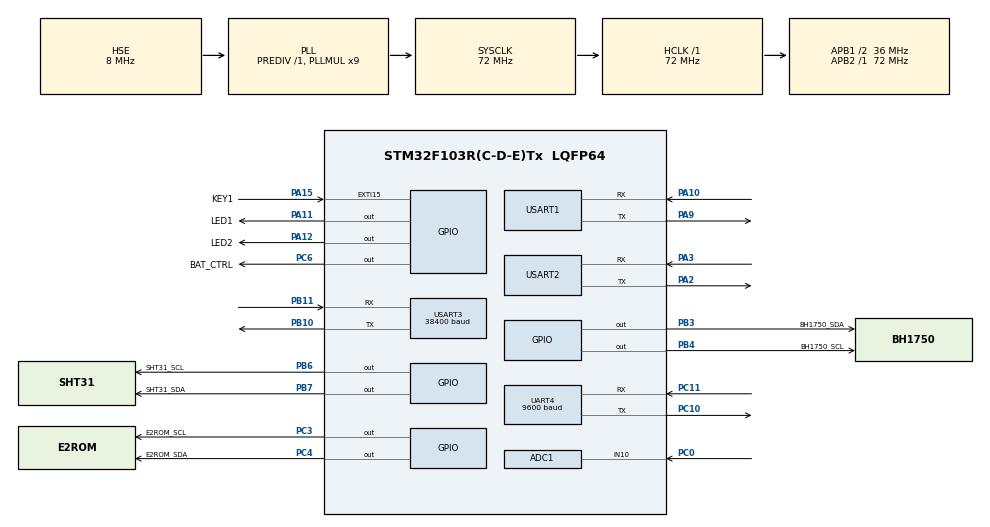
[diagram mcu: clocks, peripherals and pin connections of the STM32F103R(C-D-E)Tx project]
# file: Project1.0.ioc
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ADC1.Channel-0\#ChannelRegularConversion=ADC_CHANNEL_10
ADC1.NbrOfConversionFlag=1
ADC1.Rank-0\#ChannelRegularConversion=1
ADC1.SamplingTime-0\#ChannelRegularConversion=ADC_SAMPLETIME_1CYCLE_5
ADC1.master=1
Dma.Request0=USART2_TX
Dma.Request1=USART2_RX
Dma.Request2=USART3_RX
Dma.USART2_RX.1.Direction=DMA_PERIPH_TO_MEMORY
Dma.USART2_RX.1.Instance=DMA1_Channel6
Dma.USART2_RX.1.MemDataAlignment=DMA_MDATAALIGN_BYTE
Dma.USART2_RX.1.MemInc=DMA_MINC_ENABLE
Dma.USART2_RX.1.Mode=DMA_NORMAL
Dma.USART2_RX.1.PeriphDataAlignment=DMA_PDATAALIGN_BYTE
Dma.USART2_RX.1.PeriphInc=DMA_PINC_DISABLE
Dma.USART2_RX.1.Priority=DMA_PRIORITY_HIGH
Dma.USART2_TX.0.Direction=DMA_MEMORY_TO_PERIPH
Dma.USART2_TX.0.Instance=DMA1_Channel7
Dma.USART2_TX.0.MemDataAlignment=DMA_MDATAALIGN_BYTE
Dma.USART2_TX.0.MemInc=DMA_MINC_ENABLE
Dma.USART2_TX.0.Mode=DMA_NORMAL
Dma.USART2_TX.0.PeriphDataAlignment=DMA_PDATAALIGN_BYTE
Dma.USART2_TX.0.PeriphInc=DMA_PINC_DISABLE
Dma.USART2_TX.0.Priority=DMA_PRIORITY_MEDIUM
Dma.USART3_RX.2.Direction=DMA_PERIPH_TO_MEMORY
Dma.USART3_RX.2.Instance=DMA1_Channel3
Dma.USART3_RX.2.MemDataAlignment=DMA_MDATAALIGN_BYTE
Dma.USART3_RX.2.MemInc=DMA_MINC_ENABLE
Dma.USART3_RX.2.Mode=DMA_NORMAL
Dma.USART3_RX.2.PeriphDataAlignment=DMA_PDATAALIGN_BYTE
Dma.USART3_RX.2.PeriphInc=DMA_PINC_DISABLE
Dma.USART3_RX.2.Priority=DMA_PRIORITY_MEDIUM
IWDG.Prescaler=IWDG_PRESCALER_256
Mcu.Family=STM32F1
Mcu.Name=STM32F103R(C-D-E)Tx
Mcu.Package=LQFP64
NVIC.DMA1_Channel3_IRQn=true\:0\:0\:false\:false\:true\:false\:true
NVIC.DMA1_Channel6_IRQn=true\:0\:0\:true\:false\:true\:false\:true
NVIC.DMA1_Channel7_IRQn=true\:0\:0\:true\:false\:true\:false\:true
NVIC.EXTI15_10_IRQn=true\:9\:0\:true\:false\:true\:true\:true
NVIC.PriorityGroup=NVIC_PRIORITYGROUP_4
NVIC.TIM6_IRQn=true\:8\:0\:true\:false\:true\:true\:true
NVIC.TIM7_IRQn=true\:10\:0\:true\:false\:true\:true\:true
NVIC.UART4_IRQn=true\:6\:0\:true\:false\:true\:true\:true
NVIC.USART1_IRQn=true\:7\:0\:true\:false\:true\:true\:true
NVIC.USART2_IRQn=true\:5\:0\:true\:false\:true\:true\:true
NVIC.USART3_IRQn=true\:6\:0\:true\:false\:true\:true\:true
PA10.Mode=Asynchronous
PA10.Signal=USART1_RX
PA11.GPIO_Label=LED1
PA11.Signal=GPIO_Output
PA12.GPIO_Label=LED2
PA12.Signal=GPIO_Output
PA13.Mode=Serial_Wire
PA13.Signal=SYS_JTMS-SWDIO
PA14.Mode=Serial_Wire
PA14.Signal=SYS_JTCK-SWCLK
PA15.GPIO_Label=KEY1
PA15.Signal=GPXTI15
PA2.Mode=Asynchronous
PA2.Signal=USART2_TX
PA3.Mode=Asynchronous
PA3.Signal=USART2_RX
PA9.Mode=Asynchronous
PA9.Signal=USART1_TX
PB10.Mode=Asynchronous
PB10.Signal=USART3_TX
PB11.Mode=Asynchronous
PB11.Signal=USART3_RX
PB3.GPIO_Label=BH1750_SDA
PB3.GPIO_ModeDefaultOutputPP=GPIO_MODE_OUTPUT_OD
PB3.GPIO_Speed=GPIO_SPEED_FREQ_HIGH
PB3.PinState=GPIO_PIN_SET
PB3.Signal=GPIO_Output
PB4.GPIO_Label=BH1750_SCL
PB4.GPIO_ModeDefaultOutputPP=GPIO_MODE_OUTPUT_OD
PB4.GPIO_Speed=GPIO_SPEED_FREQ_HIGH
PB4.PinState=GPIO_PIN_SET
PB4.Signal=GPIO_Output
PB6.GPIO_Label=SHT31_SCL
PB6.GPIO_ModeDefaultOutputPP=GPIO_MODE_OUTPUT_OD
PB6.GPIO_Speed=GPIO_SPEED_FREQ_HIGH
PB6.PinState=GPIO_PIN_SET
PB6.Signal=GPIO_Output
PB7.GPIO_Label=SHT31_SDA
PB7.GPIO_ModeDefaultOutputPP=GPIO_MODE_OUTPUT_OD
PB7.GPIO_Speed=GPIO_SPEED_FREQ_HIGH
PB7.PinState=GPIO_PIN_SET
PB7.Signal=GPIO_Output
PC0.Signal=ADCx_IN10
PC10.Mode=Asynchronous
PC10.Signal=UART4_TX
PC11.Mode=Asynchronous
PC11.Signal=UART4_RX
PC3.GPIO_Label=E2ROM_SCL
PC3.GPIO_ModeDefaultOutputPP=GPIO_MODE_OUTPUT_OD
PC3.GPIO_Speed=GPIO_SPEED_FREQ_MEDIUM
PC3.PinState=GPIO_PIN_SET
PC3.Signal=GPIO_Output
PC4.GPIO_Label=E2ROM_SDA
PC4.GPIO_ModeDefaultOutputPP=GPIO_MODE_OUTPUT_OD
PC4.GPIO_Speed=GPIO_SPEED_FREQ_MEDIUM
PC4.PinState=GPIO_PIN_SET
PC4.Signal=GPIO_Output
PC6.GPIO_Label=BAT_CTRL
PC6.GPIO_Speed=GPIO_SPEED_FREQ_MEDIUM
PC6.PinState=GPIO_PIN_SET
PC6.Signal=GPIO_Output
PD0-OSC_IN.Mode=HSE-External-Oscillator
PD0-OSC_IN.Signal=RCC_OSC_IN
PD1-OSC_OUT.Mode=HSE-External-Oscillator
PD1-OSC_OUT.Signal=RCC_OSC_OUT
ProjectManager.HeapSize=0x200
ProjectManager.StackSize=0x400
ProjectManager.TargetToolchain=MDK-ARM V5.27
RCC.ADCPresc=RCC_ADCPCLK2_DIV6
RCC.AHBFreq_Value=72000000
RCC.APB1CLKDivider=RCC_HCLK_DIV2
RCC.APB1Freq_Value=36000000
RCC.APB1TimFreq_Value=72000000
RCC.APB2Freq_Value=72000000
RCC.APB2TimFreq_Value=72000000
RCC.HCLKFreq_Value=72000000
RCC.PLLMUL=RCC_PLL_MUL9
RCC.PLLSourceVirtual=RCC_PLLSOURCE_HSE
RCC.SYSCLKFreq_VALUE=72000000
RCC.SYSCLKSource=RCC_SYSCLKSOURCE_PLLCLK
RCC.USBFreq_Value=72000000
SH.ADCx_IN10.0=ADC1_IN10,IN10
TIM6.AutoReloadPreload=TIM_AUTORELOAD_PRELOAD_ENABLE
TIM6.Period=5000
TIM6.Prescaler=71
TIM7.AutoReloadPreload=TIM_AUTORELOAD_PRELOAD_ENABLE
TIM7.Period=50000
TIM7.Prescaler=71
UART4.BaudRate=9600
UART4.VirtualMode=Asynchronous
USART1.VirtualMode=VM_ASYNC
USART2.VirtualMode=VM_ASYNC
USART3.BaudRate=38400
USART3.VirtualMode=VM_ASYNC
VP_IWDG_VS_IWDG.Mode=IWDG_Activate
VP_TIM6_VS_ClockSourceINT.Mode=Enable_Timer
VP_TIM7_VS_ClockSourceINT.Mode=Enable_Timer
board=custom

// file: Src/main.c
/* USER CODE BEGIN Header */
/**
  ******************************************************************************
  * @file           : main.c
  * @brief          : Main program body
  ******************************************************************************
  * @attention
  *
  * <h2><center>&copy; Copyright (c) 2022 STMicroelectronics.
  * All rights reserved.</center></h2>
  *
  * This software component is licensed by ST under BSD 3-Clause license,
  * the "License"; You may not use this file except in compliance with the
  * License. You may obtain a copy of the License at:
  *                        opensource.org/licenses/BSD-3-Clause
  *
  ******************************************************************************
  */
/* USER CODE END Header */

#include "main.h"
#include "adc.h"
#include "dma.h"
#include "iwdg.h"
#include "tim.h"
#include "usart.h"
#include "gpio.h"

/* USER CODE BEGIN Includes */
#include "Myapplication.h"
/* USER CODE END Includes */

void SystemClock_Config(void);

int main(void)
{

  /* MCU Configuration--------------------------------------------------------*/

  /* Reset of all peripherals, Initializes the Flash interface and the Systick. */
  HAL_Init();

  /* Configure the system clock */
  SystemClock_Config();

  /* Initialize all configured peripherals */
  MX_GPIO_Init();
  MX_DMA_Init();
  MX_USART1_UART_Init();
  MX_TIM6_Init();
  MX_UART4_Init();
  MX_USART2_UART_Init();
  MX_USART3_UART_Init();
  MX_ADC1_Init();
  MX_IWDG_Init();
  MX_TIM7_Init();
  /* USER CODE BEGIN 2 */
  MyInit.Peripheral_Set();
  /* USER CODE END 2 */

  /* Infinite loop */
  while (1)
  {

    /* USER CODE BEGIN 3 */
		System.Run();
  }
  /* USER CODE END 3 */
}

void SystemClock_Config(void)
{
  RCC_OscInitTypeDef RCC_OscInitStruct = {0};
  RCC_ClkInitTypeDef RCC_ClkInitStruct = {0};
  RCC_PeriphCLKInitTypeDef PeriphClkInit = {0};

  /** Initializes the CPU, AHB and APB busses clocks
  */
  RCC_OscInitStruct.OscillatorType = RCC_OSCILLATORTYPE_LSI|RCC_OSCILLATORTYPE_HSE;
  RCC_OscInitStruct.HSEState = RCC_HSE_ON;
  RCC_OscInitStruct.HSEPredivValue = RCC_HSE_PREDIV_DIV1;
  RCC_OscInitStruct.HSIState = RCC_HSI_ON;
  RCC_OscInitStruct.LSIState = RCC_LSI_ON;
  RCC_OscInitStruct.PLL.PLLState = RCC_PLL_ON;
  RCC_OscInitStruct.PLL.PLLSource = RCC_PLLSOURCE_HSE;
  RCC_OscInitStruct.PLL.PLLMUL = RCC_PLL_MUL9;
  if (HAL_RCC_OscConfig(&RCC_OscInitStruct) != HAL_OK)
  {
    Error_Handler();
  }
  /** Initializes the CPU, AHB and APB busses clocks
  */
  RCC_ClkInitStruct.ClockType = RCC_CLOCKTYPE_HCLK|RCC_CLOCKTYPE_SYSCLK
                              |RCC_CLOCKTYPE_PCLK1|RCC_CLOCKTYPE_PCLK2;
  RCC_ClkInitStruct.SYSCLKSource = RCC_SYSCLKSOURCE_PLLCLK;
  RCC_ClkInitStruct.AHBCLKDivider = RCC_SYSCLK_DIV1;
  RCC_ClkInitStruct.APB1CLKDivider = RCC_HCLK_DIV2;
  RCC_ClkInitStruct.APB2CLKDivider = RCC_HCLK_DIV1;

  if (HAL_RCC_ClockConfig(&RCC_ClkInitStruct, FLASH_LATENCY_2) != HAL_OK)
  {
    Error_Handler();
  }
  PeriphClkInit.PeriphClockSelection = RCC_PERIPHCLK_ADC;
  PeriphClkInit.AdcClockSelection = RCC_ADCPCLK2_DIV6;
  if (HAL_RCCEx_PeriphCLKConfig(&PeriphClkInit) != HAL_OK)
  {
    Error_Handler();
  }
}

void Error_Handler(void)
{
}

/************************ (C) COPYRIGHT STMicroelectronics *****END OF FILE****/
